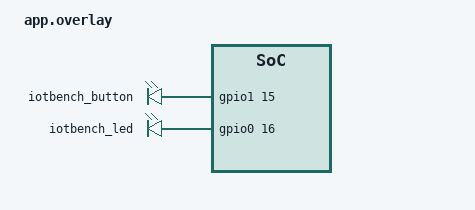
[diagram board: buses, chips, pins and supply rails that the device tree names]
&i2c0 {
	compatible = "nordic,nrf-twi";
};

/ {
	iotbench_gpios {
		compatible = "gpio-leds";
		iotbench_button: iotbench_button {
			gpios = <&gpio1 15 GPIO_ACTIVE_HIGH>;
		};
		iotbench_led: iotbench_led {
			gpios = <&gpio0 16 GPIO_ACTIVE_HIGH>;
		};
	};
	aliases {
		my-button = &iotbench_button;
		my-led = &iotbench_led;
	};
};
